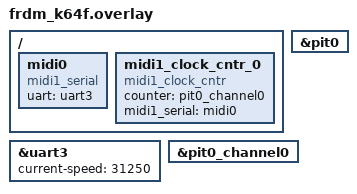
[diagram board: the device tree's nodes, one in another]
/*
 * SPDX-License-Identifier: Apache-2.0
 */

/**
 * @file frdm_k64f.overlay
 * @brief Combined overlay for hybrid MIDI test on K64F
 */

/ {
	midi0: midi0 {
		status = "okay";
		compatible = "midi1_serial";
		uart = <&uart3>;
	};

	midi1_clock_cntr_0: midi1_clock_cntr_0 {
		compatible = "midi1_clock_cntr";
		counter = <&pit0_channel0>;
		midi1_serial = <&midi0>;
		status = "okay";
	};
};

&uart3 {
	status = "okay";
	current-speed = <31250>;
};

&pit0 {
	status = "okay";
};

&pit0_channel0 {
	status = "okay";
};
